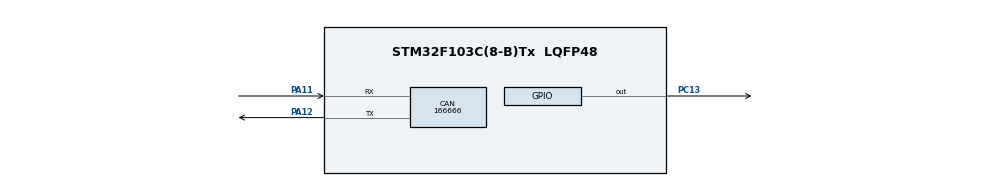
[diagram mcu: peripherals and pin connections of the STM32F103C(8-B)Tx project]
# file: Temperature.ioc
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CAN.CalculateBaudRate=166666
CAN.CalculateTimeBit=6000
CAN.CalculateTimeQuantum=2000.0
Mcu.Family=STM32F1
Mcu.Name=STM32F103C(8-B)Tx
Mcu.Package=LQFP48
NVIC.PriorityGroup=NVIC_PRIORITYGROUP_4
PA0-WKUP.Mode=SYS_WakeUp0
PA0-WKUP.Signal=SYS_WKUP
PA10.Signal=USART1_RX
PA11.Mode=CAN_Activate
PA11.Signal=CAN_RX
PA12.Mode=CAN_Activate
PA12.Signal=CAN_TX
PA13.Signal=SYS_JTMS-SWDIO
PA14.Signal=SYS_JTCK-SWCLK
PA2.Signal=USART2_TX
PA3.Signal=USART2_RX
PA4.Signal=SPI1_NSS
PA5.Signal=SPI1_SCK
PA6.Signal=SPI1_MISO
PA7.Signal=SPI1_MOSI
PA9.Signal=USART1_TX
PB10.Signal=USART3_TX
PB11.Signal=USART3_RX
PB12.Signal=SPI2_NSS
PB13.Signal=SPI2_SCK
PB14.Signal=SPI2_MISO
PB15.Signal=SPI2_MOSI
PB2.Signal=EVENTOUT
PB6.Signal=I2C1_SCL
PB7.Signal=I2C1_SDA
PC13-TAMPER-RTC.Signal=GPIO_Output
PC14-OSC32_IN.Signal=RCC_OSC32_IN
PC15-OSC32_OUT.Signal=RCC_OSC32_OUT
ProjectManager.HeapSize=0x200
ProjectManager.StackSize=0x400
ProjectManager.TargetToolchain=CMake
RCC.APB1Freq_Value=8000000
RCC.APB2Freq_Value=8000000
VP_SYS_VS_ND.Mode=No_Debug
board=custom

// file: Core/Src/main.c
/* USER CODE BEGIN Header */
/**
  ******************************************************************************
  * @file           : main.c
  * @brief          : Main program body
  ******************************************************************************
  * @attention
  *
  * Copyright (c) 2025 STMicroelectronics.
  * All rights reserved.
  *
  * This software is licensed under terms that can be found in the LICENSE file
  * in the root directory of this software component.
  * If no LICENSE file comes with this software, it is provided AS-IS.
  *
  ******************************************************************************
  */
/* USER CODE END Header */
#include "main.h"

/* USER CODE BEGIN Includes */
#include "bsp.h"
#include "app.h"
/* USER CODE END Includes */

CAN_HandleTypeDef hcan;

void SystemClock_Config(void);
static void MX_GPIO_Init(void);
static void MX_CAN_Init(void);

int main(void)
{

  /* MCU Configuration--------------------------------------------------------*/

  /* Reset of all peripherals, Initializes the Flash interface and the Systick. */
  HAL_Init();

  /* Configure the system clock */
  SystemClock_Config();

  /* Initialize all configured peripherals */
  MX_GPIO_Init();
  MX_CAN_Init();
  /* USER CODE BEGIN 2 */
  /* Initialize BSP (Board Support Package) - BSP only wraps HAL, doesn't re-init */
  if (BSP_Init() != HAL_OK)
  {
    Error_Handler();
  }
  /* Initialize Application */
  App_Init();
  /* USER CODE END 2 */

  /* Infinite loop */
  while (1)
  {

    /* USER CODE BEGIN 3 */
    App_Process();
  }
  /* USER CODE END 3 */
}

void SystemClock_Config(void)
{
  RCC_OscInitTypeDef RCC_OscInitStruct = {0};
  RCC_ClkInitTypeDef RCC_ClkInitStruct = {0};

  /** Initializes the RCC Oscillators according to the specified parameters
  * in the RCC_OscInitTypeDef structure.
  */
  RCC_OscInitStruct.OscillatorType = RCC_OSCILLATORTYPE_HSI;
  RCC_OscInitStruct.HSIState = RCC_HSI_ON;
  RCC_OscInitStruct.HSICalibrationValue = RCC_HSICALIBRATION_DEFAULT;
  RCC_OscInitStruct.PLL.PLLState = RCC_PLL_NONE;
  if (HAL_RCC_OscConfig(&RCC_OscInitStruct) != HAL_OK)
  {
    Error_Handler();
  }

  /** Initializes the CPU, AHB and APB buses clocks
  */
  RCC_ClkInitStruct.ClockType = RCC_CLOCKTYPE_HCLK|RCC_CLOCKTYPE_SYSCLK
                              |RCC_CLOCKTYPE_PCLK1|RCC_CLOCKTYPE_PCLK2;
  RCC_ClkInitStruct.SYSCLKSource = RCC_SYSCLKSOURCE_HSI;
  RCC_ClkInitStruct.AHBCLKDivider = RCC_SYSCLK_DIV1;
  RCC_ClkInitStruct.APB1CLKDivider = RCC_HCLK_DIV1;
  RCC_ClkInitStruct.APB2CLKDivider = RCC_HCLK_DIV1;

  if (HAL_RCC_ClockConfig(&RCC_ClkInitStruct, FLASH_LATENCY_0) != HAL_OK)
  {
    Error_Handler();
  }
}

static void MX_CAN_Init(void)
{

  hcan.Instance = CAN1;
  hcan.Init.Prescaler = 16;
  hcan.Init.Mode = CAN_MODE_NORMAL;
  hcan.Init.SyncJumpWidth = CAN_SJW_1TQ;
  hcan.Init.TimeSeg1 = CAN_BS1_1TQ;
  hcan.Init.TimeSeg2 = CAN_BS2_1TQ;
  hcan.Init.TimeTriggeredMode = DISABLE;
  hcan.Init.AutoBusOff = DISABLE;
  hcan.Init.AutoWakeUp = DISABLE;
  hcan.Init.AutoRetransmission = DISABLE;
  hcan.Init.ReceiveFifoLocked = DISABLE;
  hcan.Init.TransmitFifoPriority = DISABLE;
  if (HAL_CAN_Init(&hcan) != HAL_OK)
  {
    Error_Handler();
  }

}

static void MX_GPIO_Init(void)
{
  GPIO_InitTypeDef GPIO_InitStruct = {0};

  /* GPIO Ports Clock Enable */
  __HAL_RCC_GPIOC_CLK_ENABLE();
  __HAL_RCC_GPIOA_CLK_ENABLE();
  __HAL_RCC_GPIOB_CLK_ENABLE();

  /*Configure GPIO pin Output Level */
  HAL_GPIO_WritePin(GPIOC, GPIO_PIN_13, GPIO_PIN_RESET);

  /*Configure GPIO pin : PC13 */
  GPIO_InitStruct.Pin = GPIO_PIN_13;
  GPIO_InitStruct.Mode = GPIO_MODE_OUTPUT_PP;
  GPIO_InitStruct.Pull = GPIO_NOPULL;
  GPIO_InitStruct.Speed = GPIO_SPEED_FREQ_LOW;
  HAL_GPIO_Init(GPIOC, &GPIO_InitStruct);

  /*Configure GPIO pins : PA2 PA4 PA5 PA6
                           PA7 PA9 */
  GPIO_InitStruct.Pin = GPIO_PIN_2|GPIO_PIN_4|GPIO_PIN_5|GPIO_PIN_6
                          |GPIO_PIN_7|GPIO_PIN_9;
  GPIO_InitStruct.Mode = GPIO_MODE_AF_PP;
  GPIO_InitStruct.Speed = GPIO_SPEED_FREQ_HIGH;
  HAL_GPIO_Init(GPIOA, &GPIO_InitStruct);

  /*Configure GPIO pins : PA3 PA10 */
  GPIO_InitStruct.Pin = GPIO_PIN_3|GPIO_PIN_10;
  GPIO_InitStruct.Mode = GPIO_MODE_INPUT;
  GPIO_InitStruct.Pull = GPIO_NOPULL;
  HAL_GPIO_Init(GPIOA, &GPIO_InitStruct);

  /*Configure GPIO pin : PB2 */
  GPIO_InitStruct.Pin = GPIO_PIN_2;
  GPIO_InitStruct.Mode = GPIO_MODE_AF_PP;
  GPIO_InitStruct.Speed = GPIO_SPEED_FREQ_LOW;
  HAL_GPIO_Init(GPIOB, &GPIO_InitStruct);

  /*Configure GPIO pins : PB10 PB12 PB13 PB14
                           PB15 */
  GPIO_InitStruct.Pin = GPIO_PIN_10|GPIO_PIN_12|GPIO_PIN_13|GPIO_PIN_14
                          |GPIO_PIN_15;
  GPIO_InitStruct.Mode = GPIO_MODE_AF_PP;
  GPIO_InitStruct.Speed = GPIO_SPEED_FREQ_HIGH;
  HAL_GPIO_Init(GPIOB, &GPIO_InitStruct);

  /*Configure GPIO pin : PB11 */
  GPIO_InitStruct.Pin = GPIO_PIN_11;
  GPIO_InitStruct.Mode = GPIO_MODE_INPUT;
  GPIO_InitStruct.Pull = GPIO_NOPULL;
  HAL_GPIO_Init(GPIOB, &GPIO_InitStruct);

  /*Configure GPIO pins : PB6 PB7 */
  GPIO_InitStruct.Pin = GPIO_PIN_6|GPIO_PIN_7;
  GPIO_InitStruct.Mode = GPIO_MODE_AF_OD;
  GPIO_InitStruct.Speed = GPIO_SPEED_FREQ_HIGH;
  HAL_GPIO_Init(GPIOB, &GPIO_InitStruct);

  /*Configures the port and pin on which the EVENTOUT Cortex signal will be connected */
  HAL_GPIOEx_ConfigEventout(AFIO_EVENTOUT_PORT_B, AFIO_EVENTOUT_PIN_2);

  /*Enables the Event Output */
  HAL_GPIOEx_EnableEventout();

}

void Error_Handler(void)
{
  __disable_irq();
  while (1)
  {
  }
}
